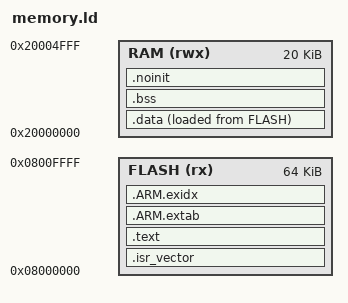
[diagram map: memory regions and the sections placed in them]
ENTRY(Reset_Handler)

MEMORY
{
    FLASH (rx)  : ORIGIN = 0x08000000, LENGTH = 64K
    RAM   (rwx) : ORIGIN = 0x20000000, LENGTH = 20K
}

_Min_Stack_Size = 0x400;
_estack = ORIGIN(RAM) + LENGTH(RAM);
_sstack = _estack - _Min_Stack_Size;

SECTIONS
{
    .isr_vector :
    {
        . = ALIGN(4);
        KEEP(*(.isr_vector))
        . = ALIGN(4);
    } > FLASH

    .text :
    {
        . = ALIGN(4);
        *(.text)
        *(.text*)
        *(.rodata)
        *(.rodata*)
        . = ALIGN(4);
        _etext = .;
    } > FLASH

    .ARM.extab :
    {
        *(.ARM.extab* .gnu.linkonce.armextab.*)
    } > FLASH

    .ARM.exidx :
    {
        __exidx_start = .;
        *(.ARM.exidx*)
        __exidx_end = .;
    } > FLASH

    _sidata = LOADADDR(.data);

    .data :
    {
        . = ALIGN(4);
        _sdata = .;
        *(.data)
        *(.data*)
        . = ALIGN(4);
        _edata = .;
    } > RAM AT > FLASH

    .bss (NOLOAD) :
    {
        . = ALIGN(4);
        _sbss = .;
        __bss_start__ = .;
        *(.bss)
        *(.bss*)
        *(COMMON)
        . = ALIGN(4);
        _ebss = .;
        __bss_end__ = .;
    } > RAM

    .noinit (NOLOAD) :
    {
        . = ALIGN(8);
        _snoinit = .;
        *(.noinit)
        *(.noinit*)
        . = ALIGN(8);
        _enoinit = .;
    } > RAM

    . = ALIGN(8);
    _end = .;
    __heap_start__ = .;
    __heap_end__ = _sstack;

    /DISCARD/ :
    {
        *(.comment)
        *(.note*)
    }

    ASSERT(_end <= _sstack,
           "RAM overflow: static data collides with reserved main stack")
}
